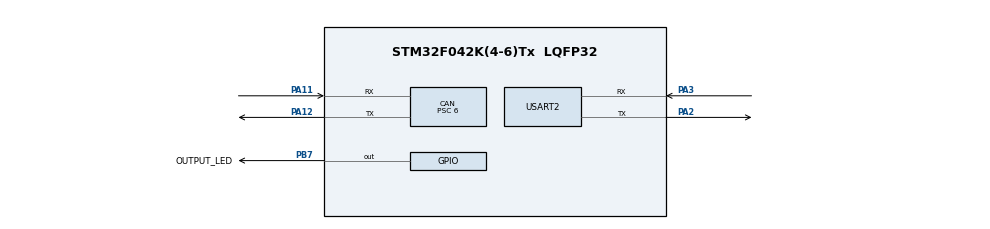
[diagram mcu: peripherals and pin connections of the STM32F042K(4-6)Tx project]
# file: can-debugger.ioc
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CAN.BS1=CAN_BS1_13TQ
CAN.BS2=CAN_BS2_2TQ
CAN.CalculateBaudRate=500000
CAN.CalculateTimeBit=2000
CAN.CalculateTimeQuantum=125.0
CAN.Prescaler=6
Mcu.Family=STM32F0
Mcu.Name=STM32F042K(4-6)Tx
Mcu.Package=LQFP32
NVIC.CEC_CAN_IRQn=true\:0\:0\:false\:false\:true\:true\:true\:true
PA11.Mode=CAN_Activate
PA11.Signal=CAN_RX
PA12.Mode=CAN_Activate
PA12.Signal=CAN_TX
PA2.Mode=Asynchronous
PA2.Signal=USART2_TX
PA3.Mode=Asynchronous
PA3.Signal=USART2_RX
PB7.GPIO_Label=OUTPUT_LED
PB7.Signal=GPIO_Output
ProjectManager.HeapSize=0x200
ProjectManager.StackSize=0x400
ProjectManager.TargetToolchain=Makefile
RCC.AHBFreq_Value=48000000
RCC.APB1Freq_Value=48000000
RCC.APB1TimFreq_Value=48000000
RCC.HCLKFreq_Value=48000000
RCC.SYSCLKFreq_VALUE=48000000
RCC.SYSCLKSource=RCC_SYSCLKSOURCE_HSI48
USART2.VirtualMode-Asynchronous=VM_ASYNC
board=custom

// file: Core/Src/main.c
/* USER CODE BEGIN Header */
/**
 ******************************************************************************
 * @file           : main.c
 * @brief          : Main program body
 ******************************************************************************
 * @attention
 *
 * Copyright (c) 2026 STMicroelectronics.
 * All rights reserved.
 *
 * This software is licensed under terms that can be found in the LICENSE file
 * in the root directory of this software component.
 * If no LICENSE file comes with this software, it is provided AS-IS.
 *
 ******************************************************************************
 */
/* USER CODE END Header */
#include "main.h"

/* USER CODE BEGIN Includes */
#include "app.h"
/* USER CODE END Includes */

CAN_HandleTypeDef hcan;

UART_HandleTypeDef huart2;

void
SystemClock_Config(void);
static void
MX_GPIO_Init(void);
static void
MX_CAN_Init(void);
static void
MX_USART2_UART_Init(void);

int
main(void) {

    /* MCU Configuration--------------------------------------------------------*/

    /* Reset of all peripherals, Initializes the Flash interface and the Systick. */
    HAL_Init();

    /* Configure the system clock */
    SystemClock_Config();

    /* Initialize all configured peripherals */
    MX_GPIO_Init();
    MX_CAN_Init();
    MX_USART2_UART_Init();
    /* USER CODE BEGIN 2 */

    app();
    /* USER CODE END 2 */

    /* Infinite loop */
    while(1) {

    }
}

void
SystemClock_Config(void) {
    RCC_OscInitTypeDef RCC_OscInitStruct = {0};
    RCC_ClkInitTypeDef RCC_ClkInitStruct = {0};

    /** Initializes the RCC Oscillators according to the specified parameters
     * in the RCC_OscInitTypeDef structure.
     */
    RCC_OscInitStruct.OscillatorType = RCC_OSCILLATORTYPE_HSI48;
    RCC_OscInitStruct.HSI48State = RCC_HSI48_ON;
    RCC_OscInitStruct.PLL.PLLState = RCC_PLL_NONE;
    if(HAL_RCC_OscConfig(&RCC_OscInitStruct) != HAL_OK) {
        Error_Handler();
    }

    /** Initializes the CPU, AHB and APB buses clocks
     */
    RCC_ClkInitStruct.ClockType = RCC_CLOCKTYPE_HCLK | RCC_CLOCKTYPE_SYSCLK | RCC_CLOCKTYPE_PCLK1;
    RCC_ClkInitStruct.SYSCLKSource = RCC_SYSCLKSOURCE_HSI48;
    RCC_ClkInitStruct.AHBCLKDivider = RCC_SYSCLK_DIV1;
    RCC_ClkInitStruct.APB1CLKDivider = RCC_HCLK_DIV1;

    if(HAL_RCC_ClockConfig(&RCC_ClkInitStruct, FLASH_LATENCY_1) != HAL_OK) {
        Error_Handler();
    }
}

static void
MX_CAN_Init(void) {

    hcan.Instance = CAN;
    hcan.Init.Prescaler = 6;
    hcan.Init.Mode = CAN_MODE_NORMAL;
    hcan.Init.SyncJumpWidth = CAN_SJW_1TQ;
    hcan.Init.TimeSeg1 = CAN_BS1_13TQ;
    hcan.Init.TimeSeg2 = CAN_BS2_2TQ;
    hcan.Init.TimeTriggeredMode = DISABLE;
    hcan.Init.AutoBusOff = DISABLE;
    hcan.Init.AutoWakeUp = DISABLE;
    hcan.Init.AutoRetransmission = DISABLE;
    hcan.Init.ReceiveFifoLocked = DISABLE;
    hcan.Init.TransmitFifoPriority = DISABLE;
    if(HAL_CAN_Init(&hcan) != HAL_OK) {
        Error_Handler();
    }
}

static void
MX_USART2_UART_Init(void) {

    huart2.Instance = USART2;
    huart2.Init.BaudRate = 38400;
    huart2.Init.WordLength = UART_WORDLENGTH_8B;
    huart2.Init.StopBits = UART_STOPBITS_1;
    huart2.Init.Parity = UART_PARITY_NONE;
    huart2.Init.Mode = UART_MODE_TX_RX;
    huart2.Init.HwFlowCtl = UART_HWCONTROL_NONE;
    huart2.Init.OverSampling = UART_OVERSAMPLING_16;
    huart2.Init.OneBitSampling = UART_ONE_BIT_SAMPLE_DISABLE;
    huart2.AdvancedInit.AdvFeatureInit = UART_ADVFEATURE_NO_INIT;
    if(HAL_UART_Init(&huart2) != HAL_OK) {
        Error_Handler();
    }
}

static void
MX_GPIO_Init(void) {
    GPIO_InitTypeDef GPIO_InitStruct = {0};

    /* GPIO Ports Clock Enable */
    __HAL_RCC_GPIOA_CLK_ENABLE();
    __HAL_RCC_GPIOB_CLK_ENABLE();

    /*Configure GPIO pin Output Level */
    HAL_GPIO_WritePin(OUTPUT_LED_GPIO_Port, OUTPUT_LED_Pin, GPIO_PIN_RESET);

    /*Configure GPIO pin : OUTPUT_LED_Pin */
    GPIO_InitStruct.Pin = OUTPUT_LED_Pin;
    GPIO_InitStruct.Mode = GPIO_MODE_OUTPUT_PP;
    GPIO_InitStruct.Pull = GPIO_NOPULL;
    GPIO_InitStruct.Speed = GPIO_SPEED_FREQ_LOW;
    HAL_GPIO_Init(OUTPUT_LED_GPIO_Port, &GPIO_InitStruct);

}

void
Error_Handler(void) {
    __disable_irq();
    while(1) {
    }
}
#ifdef USE_FULL_ASSERT
/**
 * @brief  Reports the name of the source file and the source line number
 *         where the assert_param error has occurred.
 * @param  file: pointer to the source file name
 * @param  line: assert_param error line source number
 * @retval None
 */
void
assert_failed(uint8_t *file, uint32_t line) {
    /* USER CODE BEGIN 6 */
    /* User can add his own implementation to report the file name and line
       number, ex: printf("Wrong parameters value: file %s on line %d\r\n", file,
       line) */
    /* USER CODE END 6 */
}
#endif /* USE_FULL_ASSERT */
